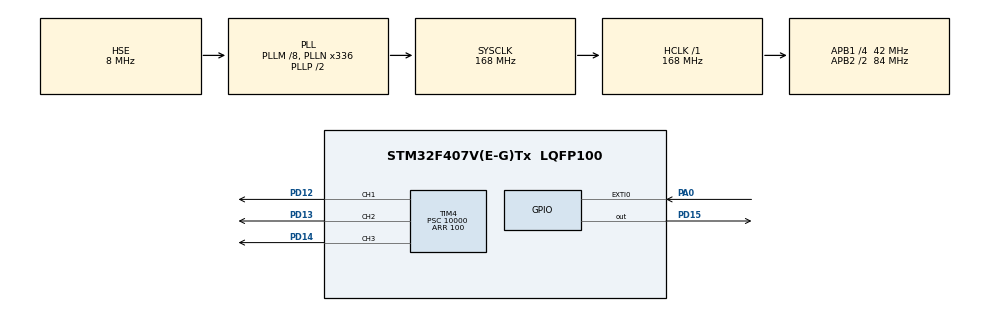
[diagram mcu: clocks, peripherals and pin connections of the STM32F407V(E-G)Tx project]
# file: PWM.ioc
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Mcu.Family=STM32F4
Mcu.Name=STM32F407V(E-G)Tx
Mcu.Package=LQFP100
NVIC.EXTI0_IRQn=true\:0\:0\:true\:false\:true
NVIC.PriorityGroup=NVIC_PRIORITYGROUP_4
PA0-WKUP.Signal=GPXTI0
PD12.Signal=S_TIM4_CH1
PD13.Signal=S_TIM4_CH2
PD14.Signal=S_TIM4_CH3
PD15.Signal=GPIO_Output
PH0-OSC_IN.Mode=HSE-External-Oscillator
PH0-OSC_IN.Signal=RCC_OSC_IN
PH1-OSC_OUT.Mode=HSE-External-Oscillator
PH1-OSC_OUT.Signal=RCC_OSC_OUT
ProjectManager.HeapSize=0x200
ProjectManager.StackSize=0x400
ProjectManager.TargetToolchain=MDK-ARM V4
RCC.48MHZClocksFreq_Value=84000000
RCC.AHBFreq_Value=168000000
RCC.APB1CLKDivider=RCC_HCLK_DIV4
RCC.APB1Freq_Value=42000000
RCC.APB1TimFreq_Value=84000000
RCC.APB2CLKDivider=RCC_HCLK_DIV2
RCC.APB2Freq_Value=84000000
RCC.APB2TimFreq_Value=168000000
RCC.CortexFreq_Value=168000000
RCC.HCLKFreq_Value=168000000
RCC.HSE_VALUE=8000000
RCC.HSI_VALUE=16000000
RCC.LSE_VALUE=32768
RCC.PLLM=8
RCC.PLLN=336
RCC.PLLSourceVirtual=RCC_PLLSOURCE_HSE
RCC.SYSCLKFreq_VALUE=168000000
RCC.SYSCLKSource=RCC_SYSCLKSOURCE_PLLCLK
RCC.VCOOutputFreq_Value=336000000
SH.S_TIM4_CH1.0=TIM4_CH1,PWM Generation1 CH1
SH.S_TIM4_CH2.0=TIM4_CH2,PWM Generation2 CH2
SH.S_TIM4_CH3.0=TIM4_CH3,PWM Generation3 CH3
TIM4.Channel-PWM\ Generation2\ CH2=TIM_CHANNEL_2
TIM4.Channel-PWM\ Generation3\ CH3=TIM_CHANNEL_3
TIM4.Period=100
TIM4.Prescaler=10000
board=PWM

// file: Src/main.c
/**
  ******************************************************************************
  * File Name          : main.c
  * Description        : Main program body
  ******************************************************************************
  *
  * COPYRIGHT(c) 2016 STMicroelectronics
  *
  * Redistribution and use in source and binary forms, with or without modification,
  * are permitted provided that the following conditions are met:
  *   1. Redistributions of source code must retain the above copyright notice,
  *      this list of conditions and the following disclaimer.
  *   2. Redistributions in binary form must reproduce the above copyright notice,
  *      this list of conditions and the following disclaimer in the documentation
  *      and/or other materials provided with the distribution.
  *   3. Neither the name of STMicroelectronics nor the names of its contributors
  *      may be used to endorse or promote products derived from this software
  *      without specific prior written permission.
  *
  * THIS SOFTWARE IS PROVIDED BY THE COPYRIGHT HOLDERS AND CONTRIBUTORS "AS IS"
  * AND ANY EXPRESS OR IMPLIED WARRANTIES, INCLUDING, BUT NOT LIMITED TO, THE
  * IMPLIED WARRANTIES OF MERCHANTABILITY AND FITNESS FOR A PARTICULAR PURPOSE ARE
  * DISCLAIMED. IN NO EVENT SHALL THE COPYRIGHT HOLDER OR CONTRIBUTORS BE LIABLE
  * FOR ANY DIRECT, INDIRECT, INCIDENTAL, SPECIAL, EXEMPLARY, OR CONSEQUENTIAL
  * DAMAGES (INCLUDING, BUT NOT LIMITED TO, PROCUREMENT OF SUBSTITUTE GOODS OR
  * SERVICES; LOSS OF USE, DATA, OR PROFITS; OR BUSINESS INTERRUPTION) HOWEVER
  * CAUSED AND ON ANY THEORY OF LIABILITY, WHETHER IN CONTRACT, STRICT LIABILITY,
  * OR TORT (INCLUDING NEGLIGENCE OR OTHERWISE) ARISING IN ANY WAY OUT OF THE USE
  * OF THIS SOFTWARE, EVEN IF ADVISED OF THE POSSIBILITY OF SUCH DAMAGE.
  *
  ******************************************************************************
  */
  // add new branch

#include "stm32f4xx_hal.h"

/* USER CODE BEGIN Includes */
// ilyes fraj
/* USER CODE END Includes */

TIM_HandleTypeDef htim4;

/* USER CODE BEGIN PV */
/* Private variables ---------------------------------------------------------*/
int i=0;
/* USER CODE END PV */

void SystemClock_Config(void);
void Error_Handler(void);
static void MX_GPIO_Init(void);
static void MX_TIM4_Init(void);

void HAL_TIM_MspPostInit(TIM_HandleTypeDef *htim);

/* USER CODE BEGIN PFP */
/* Private function prototypes -----------------------------------------------*/

/* USER CODE END PFP */

int main(void)
{

  /* MCU Configuration----------------------------------------------------------*/

  /* Reset of all peripherals, Initializes the Flash interface and the Systick. */
  HAL_Init();

  /* Configure the system clock */
  SystemClock_Config();

  /* Initialize all configured peripherals */
  MX_GPIO_Init();
  MX_TIM4_Init();

  /* USER CODE BEGIN 2 */
HAL_TIM_OC_MspInit(&htim4);
	HAL_TIM_PWM_Init(&htim4);
	HAL_TIM_OC_Start(&htim4,HAL_TIM_ACTIVE_CHANNEL_1);
	HAL_TIM_PWM_Start(&htim4,HAL_TIM_ACTIVE_CHANNEL_1);
  /* USER CODE END 2 */
// add comment
  /* Infinite loop */
  while (1)
  {
for(int i=0; i<10;i++)
		{

			HAL_Delay(20);
    }
  /* USER CODE BEGIN 3 */
HAL_TIM_OC_Stop(&htim4,HAL_TIM_ACTIVE_CHANNEL_1);
  }
  /* USER CODE END 3 */

}

/** System Clock Configuration
*/
void SystemClock_Config(void)
{

  RCC_OscInitTypeDef RCC_OscInitStruct;
  RCC_ClkInitTypeDef RCC_ClkInitStruct;

  __HAL_RCC_PWR_CLK_ENABLE();

  __HAL_PWR_VOLTAGESCALING_CONFIG(PWR_REGULATOR_VOLTAGE_SCALE1);

  RCC_OscInitStruct.OscillatorType = RCC_OSCILLATORTYPE_HSE;
  RCC_OscInitStruct.HSEState = RCC_HSE_ON;
  RCC_OscInitStruct.PLL.PLLState = RCC_PLL_ON;
  RCC_OscInitStruct.PLL.PLLSource = RCC_PLLSOURCE_HSE;
  RCC_OscInitStruct.PLL.PLLM = 8;
  RCC_OscInitStruct.PLL.PLLN = 336;
  RCC_OscInitStruct.PLL.PLLP = RCC_PLLP_DIV2;
  RCC_OscInitStruct.PLL.PLLQ = 4;
  if (HAL_RCC_OscConfig(&RCC_OscInitStruct) != HAL_OK)
  {
    Error_Handler();
  }

  RCC_ClkInitStruct.ClockType = RCC_CLOCKTYPE_HCLK|RCC_CLOCKTYPE_SYSCLK
                              |RCC_CLOCKTYPE_PCLK1|RCC_CLOCKTYPE_PCLK2;
  RCC_ClkInitStruct.SYSCLKSource = RCC_SYSCLKSOURCE_PLLCLK;
  RCC_ClkInitStruct.AHBCLKDivider = RCC_SYSCLK_DIV1;
  RCC_ClkInitStruct.APB1CLKDivider = RCC_HCLK_DIV4;
  RCC_ClkInitStruct.APB2CLKDivider = RCC_HCLK_DIV2;
  if (HAL_RCC_ClockConfig(&RCC_ClkInitStruct, FLASH_LATENCY_5) != HAL_OK)
  {
    Error_Handler();
  }

  HAL_SYSTICK_Config(HAL_RCC_GetHCLKFreq()/1000);

  HAL_SYSTICK_CLKSourceConfig(SYSTICK_CLKSOURCE_HCLK);

  /* SysTick_IRQn interrupt configuration */
  HAL_NVIC_SetPriority(SysTick_IRQn, 0, 0);
}

/* TIM4 init function */
static void MX_TIM4_Init(void)
{

  TIM_MasterConfigTypeDef sMasterConfig;
  TIM_OC_InitTypeDef sConfigOC;

  htim4.Instance = TIM4;
  htim4.Init.Prescaler = 10000;
  htim4.Init.CounterMode = TIM_COUNTERMODE_UP;
  htim4.Init.Period = 100;
  htim4.Init.ClockDivision = TIM_CLOCKDIVISION_DIV1;
  if (HAL_TIM_PWM_Init(&htim4) != HAL_OK)
  {
    Error_Handler();
  }

  sMasterConfig.MasterOutputTrigger = TIM_TRGO_RESET;
  sMasterConfig.MasterSlaveMode = TIM_MASTERSLAVEMODE_DISABLE;
  if (HAL_TIMEx_MasterConfigSynchronization(&htim4, &sMasterConfig) != HAL_OK)
  {
    Error_Handler();
  }

  sConfigOC.OCMode = TIM_OCMODE_PWM1;
  sConfigOC.Pulse = 0;
  sConfigOC.OCPolarity = TIM_OCPOLARITY_HIGH;
  sConfigOC.OCFastMode = TIM_OCFAST_DISABLE;
  if (HAL_TIM_PWM_ConfigChannel(&htim4, &sConfigOC, TIM_CHANNEL_1) != HAL_OK)
  {
    Error_Handler();
  }

  if (HAL_TIM_PWM_ConfigChannel(&htim4, &sConfigOC, TIM_CHANNEL_2) != HAL_OK)
  {
    Error_Handler();
  }

  if (HAL_TIM_PWM_ConfigChannel(&htim4, &sConfigOC, TIM_CHANNEL_3) != HAL_OK)
  {
    Error_Handler();
  }

  HAL_TIM_MspPostInit(&htim4);

}

/** Configure pins as
        * Analog
        * Input
        * Output
        * EVENT_OUT
        * EXTI
*/
static void MX_GPIO_Init(void)
{

  GPIO_InitTypeDef GPIO_InitStruct;

  /* GPIO Ports Clock Enable */
  __HAL_RCC_GPIOH_CLK_ENABLE();
  __HAL_RCC_GPIOA_CLK_ENABLE();
  __HAL_RCC_GPIOD_CLK_ENABLE();

  /*Configure GPIO pin : PA0 */
  GPIO_InitStruct.Pin = GPIO_PIN_0;
  GPIO_InitStruct.Mode = GPIO_MODE_IT_RISING;
  GPIO_InitStruct.Pull = GPIO_NOPULL;
  HAL_GPIO_Init(GPIOA, &GPIO_InitStruct);

  /*Configure GPIO pin : PD15 */
  GPIO_InitStruct.Pin = GPIO_PIN_15;
  GPIO_InitStruct.Mode = GPIO_MODE_OUTPUT_PP;
  GPIO_InitStruct.Pull = GPIO_NOPULL;
  GPIO_InitStruct.Speed = GPIO_SPEED_FREQ_LOW;
  HAL_GPIO_Init(GPIOD, &GPIO_InitStruct);

  /*Configure GPIO pin Output Level */
  HAL_GPIO_WritePin(GPIOD, GPIO_PIN_15, GPIO_PIN_RESET);

  /* EXTI interrupt init*/
  HAL_NVIC_SetPriority(EXTI0_IRQn, 0, 1);
  HAL_NVIC_EnableIRQ(EXTI0_IRQn);

}

void Error_Handler(void)
{
  while(1)
  {
  }
}

/************************ (C) COPYRIGHT STMicroelectronics *****END OF FILE****/
